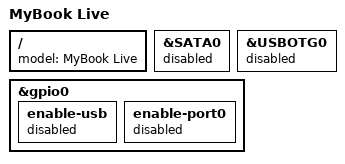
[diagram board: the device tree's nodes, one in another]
/*
 * Copyright 2008 DENX Software Engineering, Stefan Roese <sr@denx.de>
 * (c) Copyright 2010 Western Digital Technologies, Inc. All Rights Reserved.
 *
 * This file is licensed under the terms of the GNU General Public
 * License version 2.  This program is licensed "as is" without
 * any warranty of any kind, whether express or implied.
 */

/dts-v1/;

#include "apollo3g.dtsi"

/ {
	model = "MyBook Live";
};

&SATA0 {
	status = "disabled";
};

&USBOTG0 {
	status = "disabled";
};

&gpio0 {
	enable-usb {
		status = "disabled";
	};

	enable-port0 {
		status = "disabled";
	};
};
